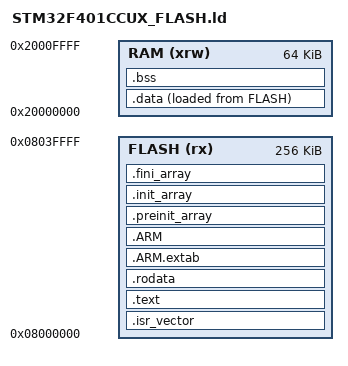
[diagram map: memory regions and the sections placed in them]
/* SPDX-License-Identifier: MIT
 *
 * Copyright (c) 2025 a5021
 *
 * Linker script for STM32F401CCU6
 *   256 KB FLASH  at 0x08000000
 *    64 KB SRAM1  at 0x20000000
 *
 * Permission is hereby granted, free of charge, to any person obtaining a copy
 * of this software and associated documentation files (the "Software"), to deal
 * in the Software without restriction, including without limitation the rights
 * to use, copy, modify, merge, publish, distribute, sublicense, and/or sell
 * copies of the Software, and to permit persons to whom the Software is
 * furnished to do so, subject to the following conditions:
 *
 * The above copyright notice and this permission notice shall be included in
 * all copies or substantial portions of the Software.
 *
 * THE SOFTWARE IS PROVIDED "AS IS", WITHOUT WARRANTY OF ANY KIND, EXPRESS OR
 * IMPLIED, INCLUDING BUT NOT LIMITED TO THE WARRANTIES OF MERCHANTABILITY,
 * FITNESS FOR A PARTICULAR PURPOSE AND NONINFRINGEMENT. IN NO EVENT SHALL THE
 * AUTHORS OR COPYRIGHT HOLDERS BE LIABLE FOR ANY CLAIM, DAMAGES OR OTHER
 * LIABILITY, WHETHER IN AN ACTION OF CONTRACT, TORT OR OTHERWISE, ARISING FROM,
 * OUT OF OR IN CONNECTION WITH THE SOFTWARE OR THE USE OR OTHER DEALINGS IN
 * THE SOFTWARE.
 */

ENTRY(Reset_Handler)

_estack = ORIGIN(RAM) + LENGTH(RAM);

_Min_Stack_Size = 0x400;

MEMORY
{
  FLASH (rx)  : ORIGIN = 0x08000000, LENGTH = 256K
  RAM   (xrw) : ORIGIN = 0x20000000, LENGTH =  64K
}

SECTIONS
{
  .isr_vector :
  {
    . = ALIGN(4);
    KEEP(*(.isr_vector))
    . = ALIGN(4);
  } >FLASH

  .text :
  {
    . = ALIGN(4);
    *(.text)
    *(.text*)
    *(.glue_7)
    *(.glue_7t)
    *(.eh_frame)

    KEEP(*(.init))
    KEEP(*(.fini))

    . = ALIGN(4);
    _etext = .;
  } >FLASH

  .rodata :
  {
    . = ALIGN(4);
    *(.rodata)
    *(.rodata*)
    . = ALIGN(4);
  } >FLASH

  .ARM.extab : { *(.ARM.extab* .gnu.linkonce.armextab.*) } >FLASH
  .ARM :
  {
    __exidx_start = .;
    *(.ARM.exidx*)
    __exidx_end = .;
  } >FLASH

  .preinit_array :
  {
    PROVIDE_HIDDEN(__preinit_array_start = .);
    KEEP(*(.preinit_array*))
    PROVIDE_HIDDEN(__preinit_array_end = .);
  } >FLASH

  .init_array :
  {
    PROVIDE_HIDDEN(__init_array_start = .);
    KEEP(*(SORT(.init_array.*)))
    KEEP(*(.init_array*))
    PROVIDE_HIDDEN(__init_array_end = .);
  } >FLASH

  .fini_array :
  {
    PROVIDE_HIDDEN(__fini_array_start = .);
    KEEP(*(SORT(.fini_array.*)))
    KEEP(*(.fini_array*))
    PROVIDE_HIDDEN(__fini_array_end = .);
  } >FLASH

  _sidata = LOADADDR(.data);

  .data :
  {
    . = ALIGN(4);
    _sdata = .;
    *(.data)
    *(.data*)
    . = ALIGN(4);
    _edata = .;
  } >RAM AT> FLASH

  .bss :
  {
    . = ALIGN(4);
    _sbss = .;
    __bss_start__ = _sbss;
    *(.bss)
    *(.bss*)
    *(COMMON)
    . = ALIGN(4);
    _ebss = .;
    __bss_end__ = _ebss;
  } >RAM

  . = ALIGN(8);
  PROVIDE(end = .);
  PROVIDE(_end = .);

  ASSERT(_estack - _end >= _Min_Stack_Size,
    "RAM overflow: .data + .bss + stack exceeds 64 KB")

  /DISCARD/ :
  {
    *(.ARM.attributes)
  }
}


